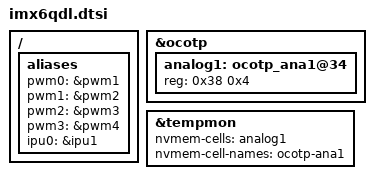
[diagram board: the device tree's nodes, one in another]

/ {
	aliases {
		pwm0 = &pwm1;
		pwm1 = &pwm2;
		pwm2 = &pwm3;
		pwm3 = &pwm4;
		ipu0 = &ipu1;
	};
};

&ocotp {
	#address-cells = <1>;
	#size-cells = <1>;

	analog1: ocotp_ana1@34 {
		reg = <0x38 0x4>;
	};
};

&tempmon {
	nvmem-cells = <&analog1>;
	nvmem-cell-names = "ocotp-ana1";
};
